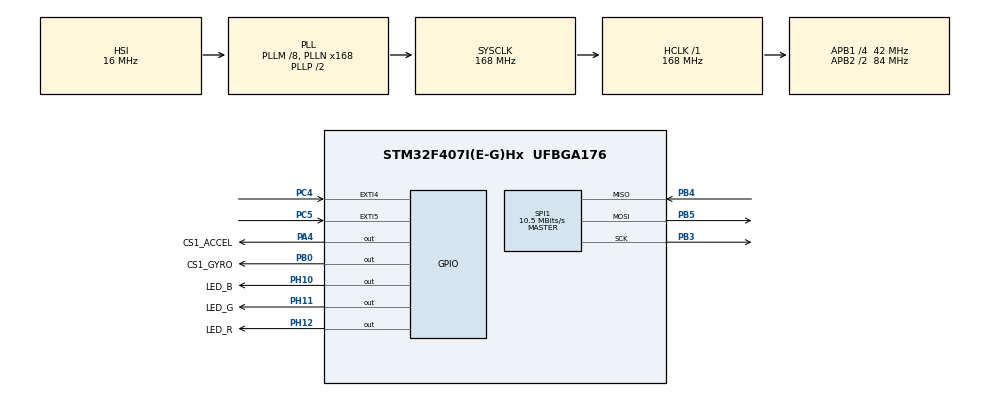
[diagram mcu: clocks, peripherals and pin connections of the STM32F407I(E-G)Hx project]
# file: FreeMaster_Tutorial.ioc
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Dma.Request0=SPI1_RX
Dma.Request1=SPI1_TX
Dma.SPI1_RX.0.Direction=DMA_PERIPH_TO_MEMORY
Dma.SPI1_RX.0.FIFOMode=DMA_FIFOMODE_DISABLE
Dma.SPI1_RX.0.Instance=DMA2_Stream2
Dma.SPI1_RX.0.MemDataAlignment=DMA_MDATAALIGN_BYTE
Dma.SPI1_RX.0.MemInc=DMA_MINC_ENABLE
Dma.SPI1_RX.0.Mode=DMA_NORMAL
Dma.SPI1_RX.0.PeriphDataAlignment=DMA_PDATAALIGN_BYTE
Dma.SPI1_RX.0.PeriphInc=DMA_PINC_DISABLE
Dma.SPI1_RX.0.Priority=DMA_PRIORITY_VERY_HIGH
Dma.SPI1_TX.1.Direction=DMA_MEMORY_TO_PERIPH
Dma.SPI1_TX.1.FIFOMode=DMA_FIFOMODE_DISABLE
Dma.SPI1_TX.1.Instance=DMA2_Stream3
Dma.SPI1_TX.1.MemDataAlignment=DMA_MDATAALIGN_BYTE
Dma.SPI1_TX.1.MemInc=DMA_MINC_ENABLE
Dma.SPI1_TX.1.Mode=DMA_NORMAL
Dma.SPI1_TX.1.PeriphDataAlignment=DMA_PDATAALIGN_BYTE
Dma.SPI1_TX.1.PeriphInc=DMA_PINC_DISABLE
Dma.SPI1_TX.1.Priority=DMA_PRIORITY_HIGH
FREERTOS.Tasks01=INSTask,24,1024,StartINSTask,Default,NULL,Dynamic,NULL,NULL;LED_G_Task,8,128,StartGLEDTask,Default,NULL,Dynamic,NULL,NULL;LED_R_Task,8,128,StartRLEDTask,Default,NULL,Dynamic,NULL,NULL
FREERTOS.configUSE_NEWLIB_REENTRANT=1
Mcu.Family=STM32F4
Mcu.Name=STM32F407I(E-G)Hx
Mcu.Package=UFBGA176
NVIC.DMA2_Stream2_IRQn=true\:5\:0\:false\:false\:true\:true\:false\:true\:true
NVIC.DMA2_Stream3_IRQn=true\:5\:0\:false\:false\:true\:true\:false\:true\:true
NVIC.PriorityGroup=NVIC_PRIORITYGROUP_4
NVIC.TIM2_IRQn=true\:15\:0\:false\:false\:true\:false\:false\:true\:true
NVIC.TimeBase=TIM2_IRQn
NVIC.TimeBaseIP=TIM2
PA13.Mode=Serial_Wire
PA13.Signal=SYS_JTMS-SWDIO
PA14.Mode=Serial_Wire
PA14.Signal=SYS_JTCK-SWCLK
PA4.GPIO_Label=CS1_ACCEL
PA4.Signal=GPIO_Output
PB0.GPIO_Label=CS1_GYRO
PB0.Signal=GPIO_Output
PB3.Mode=Full_Duplex_Master
PB3.Signal=SPI1_SCK
PB4.Mode=Full_Duplex_Master
PB4.Signal=SPI1_MISO
PB5.Mode=Full_Duplex_Master
PB5.Signal=SPI1_MOSI
PC4.Signal=GPXTI4
PC5.Signal=GPXTI5
PH0-OSC_IN.Mode=HSE-External-Oscillator
PH0-OSC_IN.Signal=RCC_OSC_IN
PH1-OSC_OUT.Mode=HSE-External-Oscillator
PH1-OSC_OUT.Signal=RCC_OSC_OUT
PH10.GPIO_Label=LED_B
PH10.GPIO_PuPd=GPIO_PULLUP
PH10.Signal=GPIO_Output
PH11.GPIO_Label=LED_G
PH11.GPIO_PuPd=GPIO_PULLUP
PH11.Signal=GPIO_Output
PH12.GPIO_Label=LED_R
PH12.GPIO_PuPd=GPIO_PULLUP
PH12.Signal=GPIO_Output
ProjectManager.HeapSize=0x200
ProjectManager.StackSize=0x400
ProjectManager.TargetToolchain=STM32CubeIDE
RCC.48MHZClocksFreq_Value=84000000
RCC.AHBFreq_Value=168000000
RCC.APB1CLKDivider=RCC_HCLK_DIV4
RCC.APB1Freq_Value=42000000
RCC.APB1TimFreq_Value=84000000
RCC.APB2CLKDivider=RCC_HCLK_DIV2
RCC.APB2Freq_Value=84000000
RCC.APB2TimFreq_Value=168000000
RCC.CortexFreq_Value=168000000
RCC.HCLKFreq_Value=168000000
RCC.HSE_VALUE=25000000
RCC.HSI_VALUE=16000000
RCC.LSE_VALUE=32768
RCC.PLLM=8
RCC.PLLN=168
RCC.SYSCLKFreq_VALUE=168000000
RCC.SYSCLKSource=RCC_SYSCLKSOURCE_PLLCLK
RCC.VCOOutputFreq_Value=336000000
SPI1.BaudRatePrescaler=SPI_BAUDRATEPRESCALER_8
SPI1.CLKPhase=SPI_PHASE_2EDGE
SPI1.CalculateBaudRate=10.5 MBits/s
SPI1.Direction=SPI_DIRECTION_2LINES
SPI1.Mode=SPI_MODE_MASTER
SPI1.VirtualType=VM_MASTER
STMicroelectronics.X-CUBE-ALGOBUILD.1.4.0.LibraryCcDSPOoLibraryJjDSPOoLibrary=true
VP_FREERTOS_VS_CMSIS_V2.Mode=CMSIS_V2
VP_STMicroelectronics.X-CUBE-ALGOBUILD_VS_DSPOoLibraryJjLibrary_1.4.0_1.4.0.Mode=DSPOoLibraryJjLibrary
VP_SYS_VS_tim2.Mode=TIM2
VP_TIM10_VS_ClockSourceINT.Mode=Enable_Timer
board=custom

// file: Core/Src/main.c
/* USER CODE BEGIN Header */
/**
  ******************************************************************************
  * @file           : main.c
  * @brief          : Main program body
  ******************************************************************************
  * @attention
  *
  * Copyright (c) 2025 STMicroelectronics.
  * All rights reserved.
  *
  * This software is licensed under terms that can be found in the LICENSE file
  * in the root directory of this software component.
  * If no LICENSE file comes with this software, it is provided AS-IS.
  *
  ******************************************************************************
  */
/* USER CODE END Header */
#include "main.h"
#include "cmsis_os.h"
#include "dma.h"
#include "spi.h"
#include "tim.h"
#include "gpio.h"

void SystemClock_Config(void);
void MX_FREERTOS_Init(void);

int main(void)
{

  /* MCU Configuration--------------------------------------------------------*/

  /* Reset of all peripherals, Initializes the Flash interface and the Systick. */
  HAL_Init();

  /* Configure the system clock */
  SystemClock_Config();

  /* Initialize all configured peripherals */
  MX_GPIO_Init();
  MX_DMA_Init();
  MX_SPI1_Init();
  MX_TIM10_Init();

  /* Init scheduler */
  osKernelInitialize();  /* Call init function for freertos objects (in cmsis_os2.c) */
  MX_FREERTOS_Init();

  /* Start scheduler */
  osKernelStart();

  /* We should never get here as control is now taken by the scheduler */

  /* Infinite loop */
  while (1)
  {

  }
}

void SystemClock_Config(void)
{
  RCC_OscInitTypeDef RCC_OscInitStruct = {0};
  RCC_ClkInitTypeDef RCC_ClkInitStruct = {0};

  /** Configure the main internal regulator output voltage
  */
  __HAL_RCC_PWR_CLK_ENABLE();
  __HAL_PWR_VOLTAGESCALING_CONFIG(PWR_REGULATOR_VOLTAGE_SCALE1);

  /** Initializes the RCC Oscillators according to the specified parameters
  * in the RCC_OscInitTypeDef structure.
  */
  RCC_OscInitStruct.OscillatorType = RCC_OSCILLATORTYPE_HSI;
  RCC_OscInitStruct.HSIState = RCC_HSI_ON;
  RCC_OscInitStruct.HSICalibrationValue = RCC_HSICALIBRATION_DEFAULT;
  RCC_OscInitStruct.PLL.PLLState = RCC_PLL_ON;
  RCC_OscInitStruct.PLL.PLLSource = RCC_PLLSOURCE_HSI;
  RCC_OscInitStruct.PLL.PLLM = 8;
  RCC_OscInitStruct.PLL.PLLN = 168;
  RCC_OscInitStruct.PLL.PLLP = RCC_PLLP_DIV2;
  RCC_OscInitStruct.PLL.PLLQ = 4;
  if (HAL_RCC_OscConfig(&RCC_OscInitStruct) != HAL_OK)
  {
    Error_Handler();
  }

  /** Initializes the CPU, AHB and APB buses clocks
  */
  RCC_ClkInitStruct.ClockType = RCC_CLOCKTYPE_HCLK|RCC_CLOCKTYPE_SYSCLK
                              |RCC_CLOCKTYPE_PCLK1|RCC_CLOCKTYPE_PCLK2;
  RCC_ClkInitStruct.SYSCLKSource = RCC_SYSCLKSOURCE_PLLCLK;
  RCC_ClkInitStruct.AHBCLKDivider = RCC_SYSCLK_DIV1;
  RCC_ClkInitStruct.APB1CLKDivider = RCC_HCLK_DIV4;
  RCC_ClkInitStruct.APB2CLKDivider = RCC_HCLK_DIV2;

  if (HAL_RCC_ClockConfig(&RCC_ClkInitStruct, FLASH_LATENCY_5) != HAL_OK)
  {
    Error_Handler();
  }
}

void HAL_TIM_PeriodElapsedCallback(TIM_HandleTypeDef *htim)
{
  if (htim->Instance == TIM2)
  {
    HAL_IncTick();
  }
}

void Error_Handler(void)
{
  __disable_irq();
  while (1)
  {
  }
}

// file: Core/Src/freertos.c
/* USER CODE BEGIN Header */
/**
  ******************************************************************************
  * File Name          : freertos.c
  * Description        : Code for freertos applications
  ******************************************************************************
  * @attention
  *
  * Copyright (c) 2025 STMicroelectronics.
  * All rights reserved.
  *
  * This software is licensed under terms that can be found in the LICENSE file
  * in the root directory of this software component.
  * If no LICENSE file comes with this software, it is provided AS-IS.
  *
  ******************************************************************************
  */
/* USER CODE END Header */

#include "FreeRTOS.h"
#include "task.h"
#include "main.h"
#include "cmsis_os.h"
#include "led_tasks.h"
#include "ins_task.h"

/* Definitions for INSTask */
osThreadId_t INSTaskHandle;
const osThreadAttr_t INSTask_attributes = {
  .name = "INSTask",
  .stack_size = 1024 * 4,
  .priority = (osPriority_t) osPriorityNormal,
};
/* Definitions for LED_G_Task */
osThreadId_t LED_G_TaskHandle;
const osThreadAttr_t LED_G_Task_attributes = {
  .name = "LED_G_Task",
  .stack_size = 128 * 4,
  .priority = (osPriority_t) osPriorityLow,
};
/* Definitions for LED_R_Task */
osThreadId_t LED_R_TaskHandle;
const osThreadAttr_t LED_R_Task_attributes = {
  .name = "LED_R_Task",
  .stack_size = 128 * 4,
  .priority = (osPriority_t) osPriorityLow,
};

void StartINSTask(void *argument);
void StartGLEDTask(void *argument);
void StartRLEDTask(void *argument);

void MX_FREERTOS_Init(void); /* (MISRA C 2004 rule 8.1) */

void MX_FREERTOS_Init(void) {

  /* Create the thread(s) */
  /* creation of INSTask */
  INSTaskHandle = osThreadNew(StartINSTask, NULL, &INSTask_attributes);

  /* creation of LED_G_Task */
  LED_G_TaskHandle = osThreadNew(StartGLEDTask, NULL, &LED_G_Task_attributes);

  /* creation of LED_R_Task */
  LED_R_TaskHandle = osThreadNew(StartRLEDTask, NULL, &LED_R_Task_attributes);

}

void StartINSTask(void *argument)
{
  /* USER CODE BEGIN StartINSTask */
  /* 初始化 INS 模块并在任务循环中调用 INS_Task() */
  INS_Init();
  for(;;)
  {
    INS_Task();
    osDelay(INS_TASK_PERIOD); /* INS_TASK_PERIOD 以 ms 为单位 (见 Core/Tasks/ins_task.h) */
  }
  /* USER CODE END StartINSTask */
}

void StartGLEDTask(void *argument)
{
  /* USER CODE BEGIN StartGLEDTask */
  /* delegate to implementation in Core/Tasks/led_tasks.c so CubeMX regions stay clean */
  LedG_TaskRun(argument);
  /* USER CODE END StartGLEDTask */
}

void StartRLEDTask(void *argument)
{
  /* USER CODE BEGIN StartRLEDTask */
  /* delegate to implementation in Core/Tasks/led_tasks.c */
  LedR_TaskRun(argument);
  /* USER CODE END StartRLEDTask */
}
